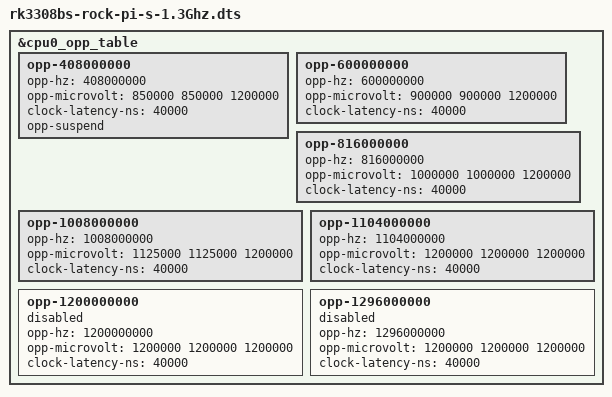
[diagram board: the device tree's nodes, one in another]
//Adjustments for Rockchip RK3308-BS suffix SOC
//https://dl.radxa.com/rockpis/docs/sw/RK3308B-S&RK3308H-S_Software_Compatibility_Introduction_V1.0.0_20211016.pdf

/dts-v1/;
/plugin/;

/ {
	fragment@0 {
		target = <&cpu0_opp_table>;
		__overlay__ {
			opp-408000000 {
				opp-hz = /bits/ 64 <408000000>;
				opp-microvolt = <850000 850000 1200000>;
				clock-latency-ns = <40000>;
				opp-suspend;
			};
			opp-600000000 {
				opp-hz = /bits/ 64 <600000000>;
				opp-microvolt = <900000 900000 1200000>;
				clock-latency-ns = <40000>;
			};
			opp-816000000 {
				opp-hz = /bits/ 64 <816000000>;
				opp-microvolt = <1000000 1000000 1200000>;
				clock-latency-ns = <40000>;
			};
			opp-1008000000 {
				opp-hz = /bits/ 64 <1008000000>;
				opp-microvolt = <1125000 1125000 1200000>;
				clock-latency-ns = <40000>;
			};
			opp-1104000000 {
				opp-hz = /bits/ 64 <1104000000>;
				opp-microvolt = <1200000 1200000 1200000>;
				clock-latency-ns = <40000>;
			};

			//the following are unsupported, overclocked operating points
			opp-1200000000 {
				opp-hz = /bits/ 64 <1200000000>;
				opp-microvolt = <1200000 1200000 1200000>;
				clock-latency-ns = <40000>;
				status = "enabled";
			};
			opp-1296000000 {
				opp-hz = /bits/ 64 <1296000000>;
				opp-microvolt = <1200000 1200000 1200000>;
				clock-latency-ns = <40000>;
				status = "enabled";
			};
		};
	};
};
